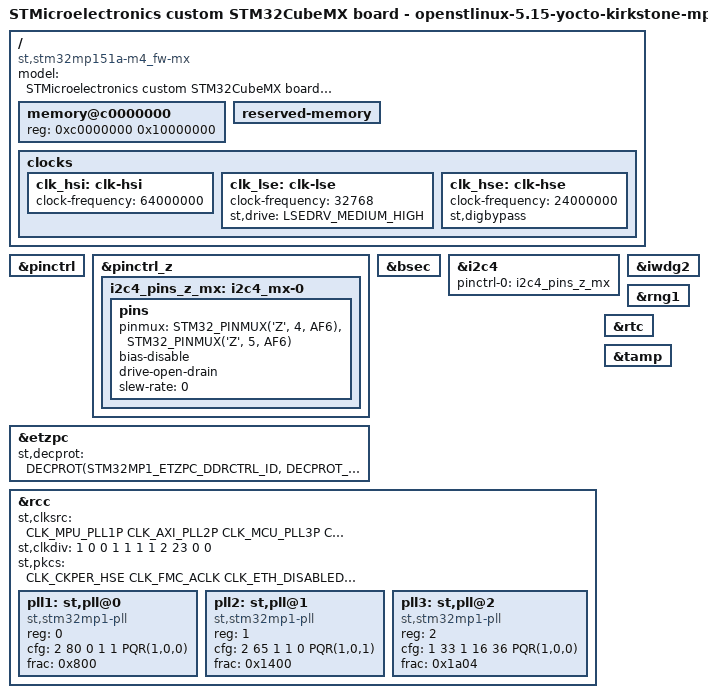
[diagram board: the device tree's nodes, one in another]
/* SPDX-License-Identifier: (GPL-2.0+ OR BSD-3-Clause) */
/*
 * Copyright (C) STMicroelectronics 2023 - All Rights Reserved
 * Author: STM32CubeMX code generation for STMicroelectronics.
 */

/* For more information on Device Tree configuration, please refer to
 * https://wiki.st.com/stm32mpu/wiki/Category:Device_tree_configuration
 */

/dts-v1/;
#include <dt-bindings/pinctrl/stm32-pinfunc.h>
#include <dt-bindings/clock/stm32mp1-clksrc.h>
#include <dt-bindings/soc/stm32mp15-etzpc.h>

#include "stm32mp151.dtsi"
#include "stm32mp15xa.dtsi"
#include "stm32mp15xxac-pinctrl.dtsi"

/* USER CODE BEGIN includes */
/* USER CODE END includes */

/ {
	model = "STMicroelectronics custom STM32CubeMX board - openstlinux-5.15-yocto-kirkstone-mp1-v22.11.23";
	compatible = "st,stm32mp151a-m4_fw-mx", "st,stm32mp151";

	memory@c0000000 {
		device_type = "memory";
		reg = <0xc0000000 0x10000000>;

		/* USER CODE BEGIN memory */
		/* USER CODE END memory */
	};

	reserved-memory {
		#address-cells = <1>;
		#size-cells = <1>;
		ranges;

		/* USER CODE BEGIN reserved-memory */
		/* USER CODE END reserved-memory */
	};

	/* USER CODE BEGIN root */
	/* USER CODE END root */

	clocks {
		/* USER CODE BEGIN clocks */
		/* USER CODE END clocks */

		clk_hsi: clk-hsi {
			clock-frequency = <64000000>;

			/* USER CODE BEGIN clk_hsi */
			/* USER CODE END clk_hsi */
		};
		clk_lse: clk-lse {
			clock-frequency = <32768>;
			st,drive = < LSEDRV_MEDIUM_HIGH >;

			/* USER CODE BEGIN clk_lse */
			/* USER CODE END clk_lse */
		};
		clk_hse: clk-hse {
			clock-frequency = <24000000>;
			st,digbypass;

			/* USER CODE BEGIN clk_hse */
			/* USER CODE END clk_hse */
		};
	};

}; /*root*/

/*Warning: the configuration of the secured GPIOs should be added in (addons) User Section*/
&pinctrl {
	/* USER CODE BEGIN pinctrl */
	/* USER CODE END pinctrl */
};

&pinctrl_z {
	i2c4_pins_z_mx: i2c4_mx-0 {
		pins {
			pinmux = <STM32_PINMUX('Z', 4, AF6)>, /* I2C4_SCL */
					 <STM32_PINMUX('Z', 5, AF6)>; /* I2C4_SDA */
			bias-disable;
			drive-open-drain;
			slew-rate = <0>;
		};
	};

	/* USER CODE BEGIN pinctrl_z */
	/* USER CODE END pinctrl_z */
};

&bsec{
	status = "okay";

	/* USER CODE BEGIN bsec */
	/* USER CODE END bsec */
};

&etzpc{
	status = "okay";
	st,decprot = <
	/*"NS_R S_W" peripherals*/
	DECPROT(STM32MP1_ETZPC_DDRCTRL_ID, DECPROT_NS_R_S_W, DECPROT_LOCK)
	DECPROT(STM32MP1_ETZPC_DDRPHYC_ID, DECPROT_NS_R_S_W, DECPROT_LOCK)
	/*"Non Secured" peripherals*/
	DECPROT(STM32MP1_ETZPC_DMA1_ID, DECPROT_NS_RW, DECPROT_UNLOCK)
	DECPROT(STM32MP1_ETZPC_DMA2_ID, DECPROT_NS_RW, DECPROT_UNLOCK)
	DECPROT(STM32MP1_ETZPC_DMAMUX_ID, DECPROT_NS_RW, DECPROT_UNLOCK)
	DECPROT(STM32MP1_ETZPC_FMC_ID, DECPROT_NS_RW, DECPROT_UNLOCK)
	DECPROT(STM32MP1_ETZPC_HASH1_ID, DECPROT_NS_RW, DECPROT_UNLOCK)
	DECPROT(STM32MP1_ETZPC_I2C4_ID, DECPROT_NS_RW, DECPROT_UNLOCK)
	DECPROT(STM32MP1_ETZPC_RNG1_ID, DECPROT_NS_RW, DECPROT_UNLOCK)
	DECPROT(STM32MP1_ETZPC_USART1_ID, DECPROT_NS_RW, DECPROT_UNLOCK)
	DECPROT(STM32MP1_ETZPC_OTG_ID, DECPROT_NS_RW, DECPROT_UNLOCK)
	/*"Secured" peripherals*/
	DECPROT(STM32MP1_ETZPC_STGENC_ID, DECPROT_S_RW, DECPROT_UNLOCK)
	/*"Mcu Isolation" peripherals*/
	DECPROT(STM32MP1_ETZPC_SPI1_ID, DECPROT_MCU_ISOLATION, DECPROT_UNLOCK)

	/*Restriction: following IDs are not managed  - please to use User-Section if needed:
		  STM32MP1_ETZPC_SRAMx_ID  STM32MP1_ETZPC_RETRAM_ID  STM32MP1_ETZPC_BKPSRAM_ID*/

	/* USER CODE BEGIN etzpc_decprot */
		/*STM32CubeMX generates a basic and standard configuration for ETZPC.
		Additional device configurations can be added here if needed.
		"etzpc" node could be also overloaded in "addons" User-Section.*/
	/* USER CODE END etzpc_decprot */
	>;

	/* USER CODE BEGIN etzpc */
	/* USER CODE END etzpc */
};

&i2c4{
	pinctrl-names = "default";
	pinctrl-0 = <&i2c4_pins_z_mx>;
	status = "okay";

	/* USER CODE BEGIN i2c4 */
	/* USER CODE END i2c4 */
};

&iwdg2{
	status = "okay";

	/* USER CODE BEGIN iwdg2 */
	/* USER CODE END iwdg2 */
};

&rcc{
	status = "okay";

	/* USER CODE BEGIN rcc */
	/* USER CODE END rcc */

	st,clksrc = <
		CLK_MPU_PLL1P
		CLK_AXI_PLL2P
		CLK_MCU_PLL3P
		CLK_PLL12_HSE
		CLK_PLL3_HSE
		CLK_PLL4_HSE
		CLK_RTC_LSE
		CLK_MCO1_DISABLED
		CLK_MCO2_DISABLED
	>;
	st,clkdiv = <
		1 		/*MPU*/
		0 		/*AXI*/
		0 		/*MCU*/
		1 		/*APB1*/
		1 		/*APB2*/
		1 		/*APB3*/
		1 		/*APB4*/
		2 		/*APB5*/
		23 		/*RTC*/
		0 		/*MCO1*/
		0 		/*MCO2*/
	>;
	st,pkcs = <
		CLK_CKPER_HSE
		CLK_FMC_ACLK
		CLK_ETH_DISABLED
		CLK_SDMMC12_DISABLED
		CLK_STGEN_HSE
		CLK_USBPHY_HSE
		CLK_SPI2S1_CKPER
		CLK_SPI2S23_DISABLED
		CLK_SPI45_DISABLED
		CLK_SPI6_DISABLED
		CLK_I2C46_HSI
		CLK_SDMMC3_DISABLED
		CLK_USBO_USBPHY
		CLK_ADC_DISABLED
		CLK_CEC_DISABLED
		CLK_I2C12_DISABLED
		CLK_I2C35_DISABLED
		CLK_UART1_HSI
		CLK_UART24_DISABLED
		CLK_UART35_DISABLED
		CLK_UART6_DISABLED
		CLK_UART78_DISABLED
		CLK_SPDIF_DISABLED
		CLK_SAI1_DISABLED
		CLK_SAI2_DISABLED
		CLK_SAI3_DISABLED
		CLK_SAI4_DISABLED
		CLK_RNG1_LSI
		CLK_LPTIM1_DISABLED
		CLK_LPTIM23_DISABLED
		CLK_LPTIM45_DISABLED
	>;
	pll1:st,pll@0 {
		compatible = "st,stm32mp1-pll";
		reg = <0>;
		cfg = < 2 80 0 1 1 PQR(1,0,0) >;
		frac = < 0x800 >;
	};
	pll2:st,pll@1 {
		compatible = "st,stm32mp1-pll";
		reg = <1>;
		cfg = < 2 65 1 1 0 PQR(1,0,1) >;
		frac = < 0x1400 >;
	};
	pll3:st,pll@2 {
		compatible = "st,stm32mp1-pll";
		reg = <2>;
		cfg = < 1 33 1 16 36 PQR(1,0,0) >;
		frac = < 0x1a04 >;
	};
};

&rng1{
	status = "okay";

	/* USER CODE BEGIN rng1 */
	/* USER CODE END rng1 */
};

&rtc{
	status = "okay";

	/* USER CODE BEGIN rtc */
	/* USER CODE END rtc */
};

&tamp{
	status = "okay";

	/* USER CODE BEGIN tamp */
	/* USER CODE END tamp */
};

/* USER CODE BEGIN addons */
/* USER CODE END addons */

